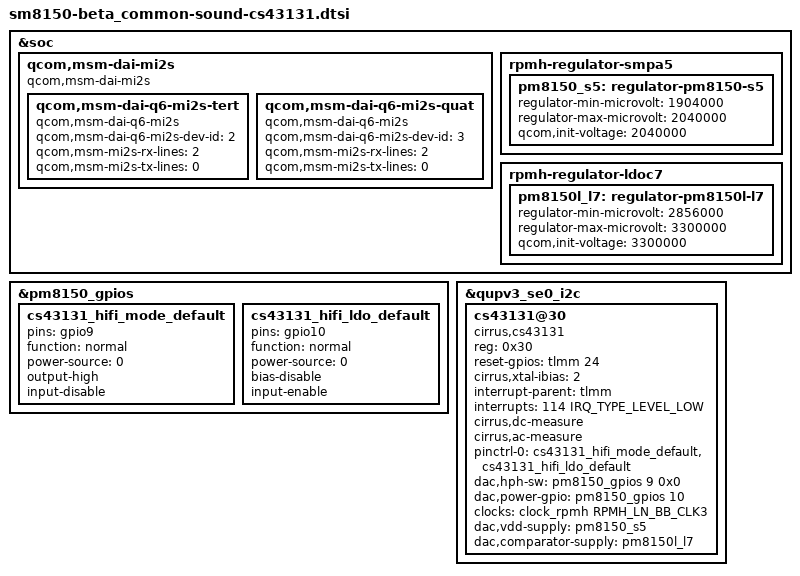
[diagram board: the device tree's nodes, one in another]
/*
 * Copyright (c) 2018, The Linux Foundation. All rights reserved.
 *
 * This program is free software; you can redistribute it and/or modify
 * it under the terms of the GNU General Public License version 2 and
 * only version 2 as published by the Free Software Foundation.
 *
 * This program is distributed in the hope that it will be useful,
 * but WITHOUT ANY WARRANTY; without even the implied warranty of
 * MERCHANTABILITY or FITNESS FOR A PARTICULAR PURPOSE.  See the
 * GNU General Public License for more details.
 */

&soc {
	qcom,msm-dai-mi2s {
		compatible = "qcom,msm-dai-mi2s";

		qcom,msm-dai-q6-mi2s-tert {
                       compatible = "qcom,msm-dai-q6-mi2s";
                       qcom,msm-dai-q6-mi2s-dev-id = <2>;
                       qcom,msm-mi2s-rx-lines = <2>; /* SD1 used as output */
                       qcom,msm-mi2s-tx-lines = <0>; /* SD0 used as input */
		};
		
		qcom,msm-dai-q6-mi2s-quat {
			compatible = "qcom,msm-dai-q6-mi2s";
			qcom,msm-dai-q6-mi2s-dev-id = <3>;
			qcom,msm-mi2s-rx-lines = <2>;
			qcom,msm-mi2s-tx-lines = <0>;
		};
	};
};

/* PMIC GPIO pin control configurations: */
&pm8150_gpios {
	cs43131_hifi_mode_default: cs43131_hifi_mode_default {
		pins = "gpio9";
		function = "normal";
		power-source = <0>;
		output-high;
		input-disable;
	};

	cs43131_hifi_ldo_default: cs43131_hifi_ldo_default {
		pins = "gpio10";
		function = "normal";
		power-source = <0>;
		bias-disable;
		input-enable;
	};
};

/* Comparator and AMP LDO Regulator Configuration */
&soc {
/* Amp LDO regulator : 2V0_VREG_S5A */
        rpmh-regulator-smpa5 {
                pm8150_s5: regulator-pm8150-s5 {
                        regulator-min-microvolt = <1904000>;
                        regulator-max-microvolt = <2040000>;
                        qcom,init-voltage = <2040000>;
                };
        };
/* Comparator Regulator : 3V3_VREG_L7C */
        rpmh-regulator-ldoc7 {
                pm8150l_l7: regulator-pm8150l-l7 {
                        regulator-min-microvolt = <2856000>;
                        regulator-max-microvolt = <3300000>;
                        qcom,init-voltage = <3300000>;
                };
        };
};

/*
Required properties:

  - compatible : "cirrus,cs43130", "cirrus,cs4399", "cirrus,cs43131",
                 "cirrus,cs43198"

  - reg : the I2C address of the device for I2C

  - VA-supply, VP-supply, VL-supply, VCP-supply, VD-supply:
	power supplies for the device, as covered in
	Documentation/devicetree/bindings/regulator/regulator.txt.


Optional properties:

  - reset-gpios : Active low GPIO used to reset the device

  - cirrus,xtal-ibias:
   When external MCLK is generated by external crystal
   oscillator, CS43130 can be used to provide bias current
   for external crystal.  Amount of bias current sent is
   set as:
   1 = 7.5uA
   2 = 12.5uA
   3 = 15uA

  - cirrus,dc-measure:
   Boolean, define to enable headphone DC impedance measurement.

  - cirrus,ac-measure:
   Boolean, define to enable headphone AC impedance measurement.
   DC impedance must also be enabled for AC impedance measurement.

  - cirrus,dc-threshold:
   Define 2 DC impedance thresholds in ohms for HP output control.
   Default values are 50 and 120 Ohms.

  - cirrus,ac-freq:
   Define the frequencies at which to measure HP AC impedance.
   Only used if "cirrus,dc-measure" is defined.
   Exactly 10 frequencies must be defined.
   If this properties is undefined, by default,
   following frequencies are used:
   <24 43 93 200 431 928 2000 4309 9283 20000>
   The above frequencies are logarithmically equally spaced.
   Log base is 10.
*/

&qupv3_se0_i2c{ /* QUPV3 SE0  */
	cs43131@30 {
		#sound-dai-cells = <1>;
		compatible = "cirrus,cs43131";
		reg = <0x30>;
		reset-gpios = <&tlmm 24 0x0>;

		cirrus,xtal-ibias = <2>;
		interrupt-parent = <&tlmm>;
		interrupts = <114 IRQ_TYPE_LEVEL_LOW>;
		cirrus,dc-measure;
		cirrus,ac-measure;

		pinctrl-names = "default";
		pinctrl-0 = <&cs43131_hifi_mode_default>,<&cs43131_hifi_ldo_default>;

		dac,hph-sw = <&pm8150_gpios 9 0x0>;
		dac,power-gpio = <&pm8150_gpios 10 0x0>;

		status = "ok";

		clock-names = "ln_bb_clk3";
		clocks = <&clock_rpmh RPMH_LN_BB_CLK3>;

		dac,vdd-supply = <&pm8150_s5>;
		dac,comparator-supply = <&pm8150l_l7>;
	};
};
